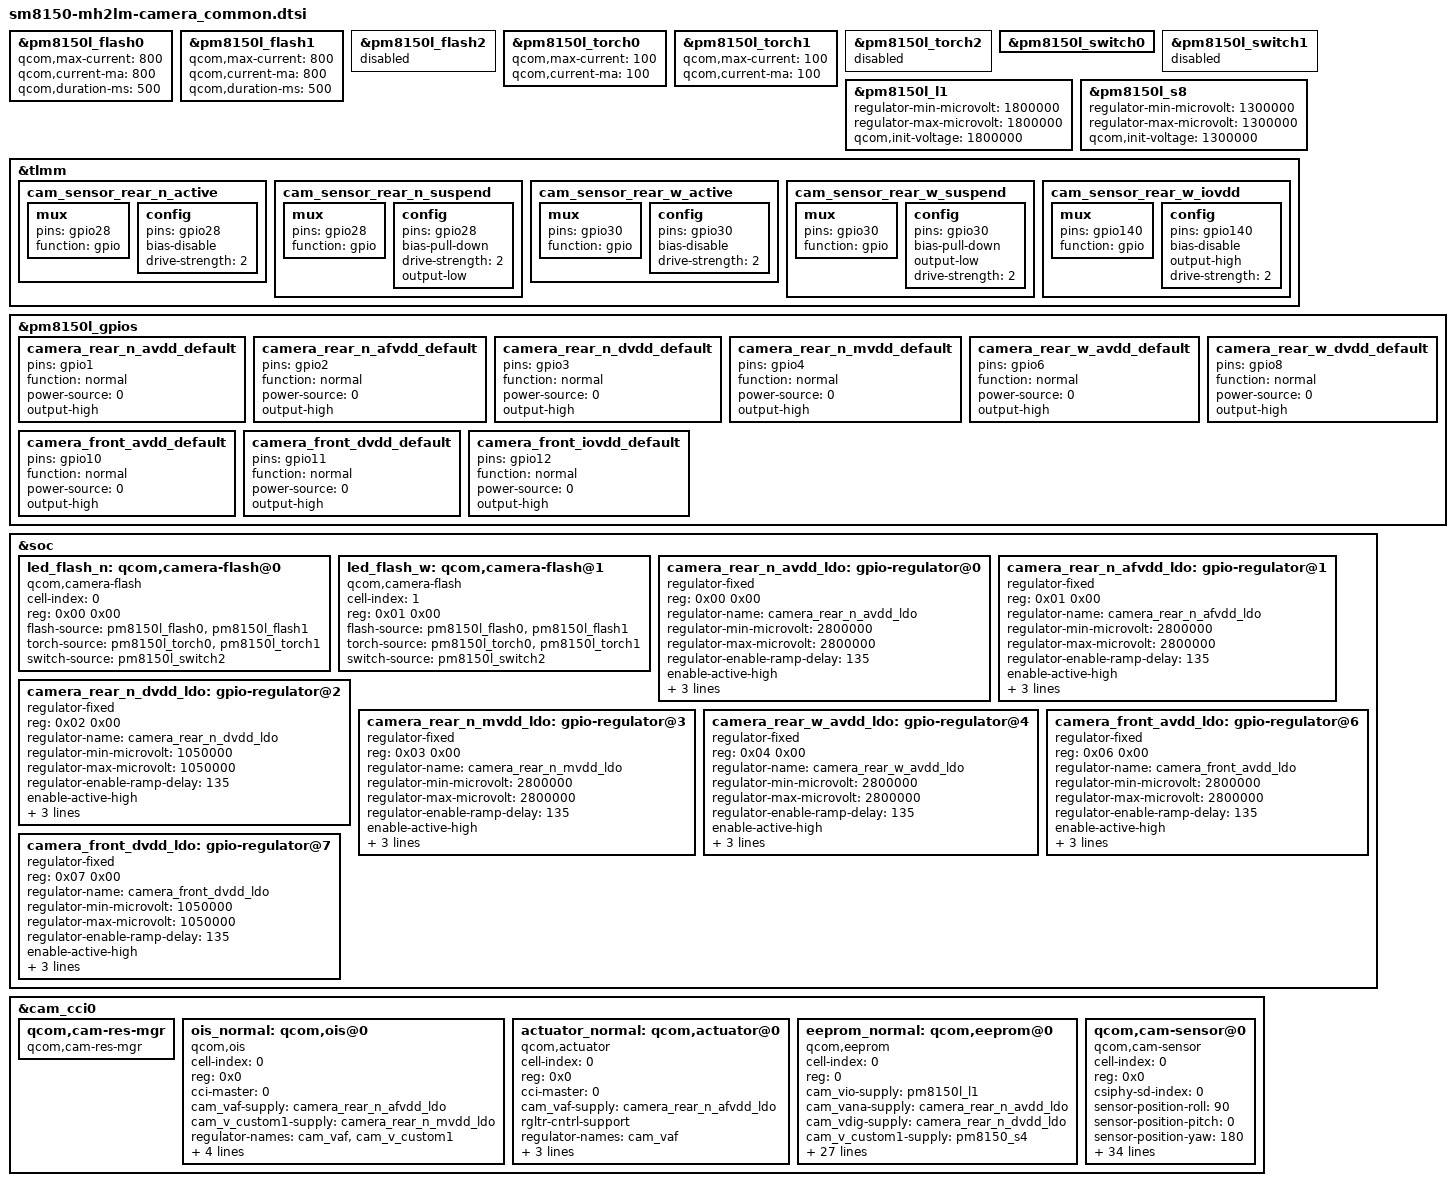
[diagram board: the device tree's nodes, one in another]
// SPDX-License-Identifier: GPL-2.0

&pm8150l_flash0 {
	status = "ok";
	qcom,max-current = <800>;
	qcom,current-ma = <800>;
	qcom,duration-ms = <500>;
};

&pm8150l_flash1 {
	status = "ok";
	qcom,max-current = <800>;
	qcom,current-ma = <800>;
	qcom,duration-ms = <500>;
};

&pm8150l_flash2 {
	status = "disabled";
};

&pm8150l_torch0 {
	status = "ok";
	qcom,max-current = <100>;
	qcom,current-ma = <100>;
};

&pm8150l_torch1 {
	status = "ok";
	qcom,max-current = <100>;
	qcom,current-ma = <100>;
};

&pm8150l_torch2 {
	status = "disabled";
};

&pm8150l_switch0 {
	status = "ok";
};

&pm8150l_switch1 {
	status = "disbled";
};

&pm8150l_l1 {
	regulator-min-microvolt = <1800000>;
	regulator-max-microvolt = <1800000>;
	qcom,init-voltage = <1800000>;
};

&pm8150l_s8 {
	regulator-min-microvolt = <1300000>;
	regulator-max-microvolt = <1300000>;
	qcom,init-voltage = <1300000>;
};

&tlmm {
	cam_sensor_rear_n_active: cam_sensor_rear_n_active {
		mux {
			pins = "gpio28";
			function = "gpio";
		};

		config {
			pins = "gpio28";
			bias-disable;
			drive-strength = <2>;
		};
	};

	cam_sensor_rear_n_suspend: cam_sensor_rear_n_suspend {
		mux {
			pins = "gpio28";
			function = "gpio";
		};

		config {
			pins = "gpio28";
			bias-pull-down;
			drive-strength = <2>;
			output-low;
		};
	};

	cam_sensor_rear_w_active: cam_sensor_rear_w_active {
		mux {
			pins = "gpio30";
			function = "gpio";
		};

		config {
			pins = "gpio30";
			bias-disable;
			drive-strength = <2>;
		};
	};

	cam_sensor_rear_w_suspend: cam_sensor_rear_w_suspend {
		mux {
			pins = "gpio30";
			function = "gpio";
		};

		config {
			pins = "gpio30";
			bias-pull-down;
			output-low;
			drive-strength = <2>;
		};
	};

	cam_sensor_rear_w_iovdd: cam_sensor_rear_w_iovdd {
		mux {
			pins = "gpio140";
			function = "gpio";
		};

		config {
			pins = "gpio140";
			bias-disable;
			output-high;
			drive-strength = <2>;
		};
	};
};

&pm8150l_gpios {
	camera_rear_n_avdd_default: camera_rear_n_avdd_default {
		pins = "gpio1";
		function = "normal";
		power-source = <0>;
		output-high;
	};

	camera_rear_n_afvdd_default: camera_rear_n_afvdd_default {
		pins = "gpio2";
		function = "normal";
		power-source = <0>;
		output-high;
	};

	camera_rear_n_dvdd_default: camera_rear_n_dvdd_default {
		pins = "gpio3";
		function = "normal";
		power-source = <0>;
		output-high;
	};

	camera_rear_n_mvdd_default: camera_rear_n_mvdd_default {
		pins = "gpio4";
		function = "normal";
		power-source = <0>;
		output-high;
	};

	camera_rear_w_avdd_default: camera_rear_w_avdd_default {
		pins = "gpio6";
		function = "normal";
		power-source = <0>;
		output-high;
	};

	camera_rear_w_dvdd_default: camera_rear_w_dvdd_default {
		pins = "gpio8";
		function = "normal";
		power-source = <0>;
		output-high;
	};

	camera_front_avdd_default: camera_front_avdd_default {
		pins = "gpio10";
		function = "normal";
		power-source = <0>;
		output-high;
	};

	camera_front_dvdd_default: camera_front_dvdd_default {
		pins = "gpio11";
		function = "normal";
		power-source = <0>;
		output-high;
	};

	camera_front_iovdd_default: camera_front_iovdd_default {
		pins = "gpio12";
		function = "normal";
		power-source = <0>;
		output-high;
	};
};

&soc {
	#address-cells = <1>;
	#size-cells = <1>;

	led_flash_n: qcom,camera-flash@0 {
		cell-index = <0>;
		reg = <0x00 0x00>;
		compatible = "qcom,camera-flash";
		flash-source = <&pm8150l_flash0 &pm8150l_flash1>;
		torch-source = <&pm8150l_torch0 &pm8150l_torch1>;
		switch-source = <&pm8150l_switch2>;
		status = "ok";
	};

	led_flash_w: qcom,camera-flash@1 {
		cell-index = <1>;
		reg = <0x01 0x00>;
		compatible = "qcom,camera-flash";
		flash-source = <&pm8150l_flash0 &pm8150l_flash1>;
		torch-source = <&pm8150l_torch0 &pm8150l_torch1>;
		switch-source = <&pm8150l_switch2>;
		status = "ok";
	};

	camera_rear_n_avdd_ldo: gpio-regulator@0 {
		compatible = "regulator-fixed";
		reg = <0x00 0x00>;
		regulator-name = "camera_rear_n_avdd_ldo";
		regulator-min-microvolt = <2800000>;
		regulator-max-microvolt = <2800000>;
		regulator-enable-ramp-delay = <135>;
		enable-active-high;
		gpio = <&pm8150l_gpios 1 0>;
		pinctrl-names = "default";
		pinctrl-0 = <&camera_rear_n_avdd_default>;
		vin-supply = <&pm8150l_bob>;
	};

	camera_rear_n_afvdd_ldo: gpio-regulator@1 {
		compatible = "regulator-fixed";
		reg = <0x01 0x00>;
		regulator-name = "camera_rear_n_afvdd_ldo";
		regulator-min-microvolt = <2800000>;
		regulator-max-microvolt = <2800000>;
		regulator-enable-ramp-delay = <135>;
		enable-active-high;
		gpio = <&pm8150l_gpios 2 0>;
		pinctrl-names = "default";
		pinctrl-0 = <&camera_rear_n_afvdd_default>;
		vin-supply = <&pm8150l_bob>;
	};

	camera_rear_n_dvdd_ldo: gpio-regulator@2 {
		compatible = "regulator-fixed";
		reg = <0x02 0x00>;
		regulator-name = "camera_rear_n_dvdd_ldo";
		regulator-min-microvolt = <1050000>;
		regulator-max-microvolt = <1050000>;
		regulator-enable-ramp-delay = <135>;
		enable-active-high;
		gpio = <&pm8150l_gpios 3 0>;
		pinctrl-names = "default";
		pinctrl-0 = <&camera_rear_n_dvdd_default>;
		vin-supply = <&pm8150_s4>;
	};

	camera_rear_n_mvdd_ldo: gpio-regulator@3 {
		compatible = "regulator-fixed";
		reg = <0x03 0x00>;
		regulator-name = "camera_rear_n_mvdd_ldo";
		regulator-min-microvolt = <2800000>;
		regulator-max-microvolt = <2800000>;
		regulator-enable-ramp-delay = <135>;
		enable-active-high;
		gpio = <&pm8150l_gpios 4 0>;
		pinctrl-names = "default";
		pinctrl-0 = <&camera_rear_n_mvdd_default>;
		vin-supply = <&pm8150l_bob>;
	};

	camera_rear_w_avdd_ldo: gpio-regulator@4 {
		compatible = "regulator-fixed";
		reg = <0x04 0x00>;
		regulator-name = "camera_rear_w_avdd_ldo";
		regulator-min-microvolt = <2800000>;
		regulator-max-microvolt = <2800000>;
		regulator-enable-ramp-delay = <135>;
		enable-active-high;
		gpio = <&pm8150l_gpios 6 0>;
		pinctrl-names = "default";
		pinctrl-0 = <&camera_rear_w_avdd_default>;
		vin-supply = <&pm8150l_bob>;
	};

	camera_front_avdd_ldo: gpio-regulator@6 {
		compatible = "regulator-fixed";
		reg = <0x06 0x00>;
		regulator-name = "camera_front_avdd_ldo";
		regulator-min-microvolt = <2800000>;
		regulator-max-microvolt = <2800000>;
		regulator-enable-ramp-delay = <135>;
		enable-active-high;
		gpio = <&pm8150l_gpios 10 0>;
		pinctrl-names = "default";
		pinctrl-0 = <&camera_front_avdd_default>;
		vin-supply = <&pm8150l_bob>;
	};

	camera_front_dvdd_ldo: gpio-regulator@7 {
		compatible = "regulator-fixed";
		reg = <0x07 0x00>;
		regulator-name = "camera_front_dvdd_ldo";
		regulator-min-microvolt = <1050000>;
		regulator-max-microvolt = <1050000>;
		regulator-enable-ramp-delay = <135>;
		enable-active-high;
		gpio = <&pm8150l_gpios 11 0>;
		pinctrl-names = "default";
		pinctrl-0 = <&camera_front_dvdd_default>;
		vin-supply = <&pm8150l_s8>;
	};
};

&cam_cci0 {
	#address-cells = <1>;
	#size-cells = <0>;

	qcom,cam-res-mgr {
		compatible = "qcom,cam-res-mgr";
		status = "ok";
	};

	ois_normal: qcom,ois@0 {
		cell-index = <0>;
		reg = <0x0>;
		compatible = "qcom,ois";
		cci-master = <0>;
		cam_vaf-supply = <&camera_rear_n_afvdd_ldo>;
		cam_v_custom1-supply = <&camera_rear_n_mvdd_ldo>;
		regulator-names = "cam_vaf","cam_v_custom1";
		rgltr-cntrl-support;
		rgltr-min-voltage = <2800000 2800000>;
		rgltr-max-voltage = <2800000 2800000>;
		rgltr-load-current = <0 0>;
		status = "ok";
	};

	actuator_normal: qcom,actuator@0 {
		cell-index = <0>;
		reg = <0x0>;
		compatible = "qcom,actuator";
		cci-master = <0>;
		cam_vaf-supply = <&camera_rear_n_afvdd_ldo>;
		rgltr-cntrl-support;
		regulator-names = "cam_vaf";
		rgltr-min-voltage = <2800000>;
		rgltr-max-voltage = <2800000>;
		rgltr-load-current = <0>;
	};

	eeprom_normal: qcom,eeprom@0 {
		cell-index = <0>;
		reg = <0>;
		compatible = "qcom,eeprom";
		cam_vio-supply = <&pm8150l_l1>;
		cam_vana-supply = <&camera_rear_n_avdd_ldo>;
		cam_vdig-supply = <&camera_rear_n_dvdd_ldo>;
		cam_v_custom1-supply = <&pm8150_s4>;
		cam_clk-supply = <&titan_top_gdsc>;
		regulator-names = "cam_vio", "cam_vana", "cam_vdig", "cam_clk", "cam_v_custom1";
		rgltr-cntrl-support;
		rgltr-min-voltage = <1800000 2800000 1050000 0 1800000>;
		rgltr-max-voltage = <1800000 2800000 1050000 0 1800000>;
		rgltr-load-current = <150000 150000 300000 0 3500000>;
		gpio-no-mux = <0>;
		pinctrl-names = "cam_default", "cam_suspend";
		pinctrl-0 = <&cam_sensor_mclk0_active
				&cam_sensor_rear_n_active>;
		pinctrl-1 = <&cam_sensor_mclk0_suspend
				&cam_sensor_rear_n_suspend>;
		gpios = <&tlmm 13 0>,
			<&tlmm 28 0>;
		gpio-reset = <1>;
		gpio-req-tbl-num = <0 1>;
		gpio-req-tbl-flags = <1 0>;
		gpio-req-tbl-label = "CAMIF_MCLK0",
					"CAM_RESET0";
		sensor-position = <0>;
		sensor-mode = <0>;
		cci-device = <0>;
		cci-master = <0>;
		status = "ok";
		clocks = <&clock_camcc CAM_CC_MCLK0_CLK>;
		clock-names = "cam_clk";
		clock-cntl-level = "turbo";
		clock-rates = <19200000>;
	};

	qcom,cam-sensor@0 {
		cell-index = <0>;
		compatible = "qcom,cam-sensor";
		reg = <0x0>;
		csiphy-sd-index = <0>;
		sensor-position-roll = <90>;
		sensor-position-pitch = <0>;
		sensor-position-yaw = <180>;
		ois-src = <&ois_normal>;
		actuator-src = <&actuator_normal>;
		eeprom-src = <&eeprom_normal>;
		led-flash-src = <&led_flash_n>;
		cam_vio-supply = <&pm8150l_l1>;
		cam_vana-supply = <&camera_rear_n_avdd_ldo>;
		cam_vdig-supply = <&camera_rear_n_dvdd_ldo>;
		cam_v_custom1-supply = <&pm8150_s4>;
		cam_clk-supply = <&titan_top_gdsc>;
		regulator-names = "cam_vio", "cam_vana", "cam_vdig", "cam_clk", "cam_v_custom1";
		rgltr-cntrl-support;
		rgltr-min-voltage = <1800000 2800000 1050000 0 1800000>;
		rgltr-max-voltage = <1800000 2800000 1050000 0 1800000>;
		rgltr-load-current = <150000 150000 300000 0 3500000>;
		gpio-no-mux = <0>;
		pinctrl-names = "cam_default", "cam_suspend";
		pinctrl-0 = <&cam_sensor_mclk0_active
				 &cam_sensor_rear_n_active>;
		pinctrl-1 = <&cam_sensor_mclk0_suspend
				 &cam_sensor_rear_n_suspend>;
		gpios = <&tlmm 13 0>,
			<&tlmm 28 0>;
		gpio-reset = <1>;
		gpio-req-tbl-num = <0 1>;
		gpio-req-tbl-flags = <1 0>;
		gpio-req-tbl-label = "CAMIF_MCLK0",
					"CAM_RESET0";
		sensor-mode = <0>;
		cci-device = <0>;
		cci-master = <0>;
		status = "ok";
		clocks = <&clock_camcc CAM_CC_MCLK0_CLK>;
		clock-names = "cam_clk";
		clock-cntl-level = "turbo";
		clock-rates = <19200000>;
	};
};
